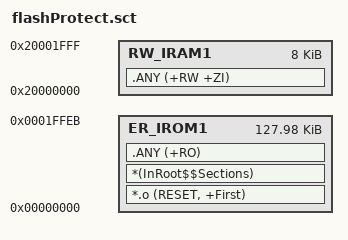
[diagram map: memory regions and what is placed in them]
; *************************************************************
; *** Scatter-Loading Description File modified so that     ***
; 0x0001ffec to 0x0001ffff aren't written by user code and  ***
; therefore can be used to store FAKEY and write protection ***
; key                                                       ***
; *************************************************************

LR_IROM1 0x00000000 0x0001ffec  {    ; load region size_region
  ER_IROM1 0x00000000 0x0001ffec  {  ; load address = execution address
   *.o (RESET, +First)
   *(InRoot$$Sections)
   .ANY (+RO)
  }
  RW_IRAM1 0x20000000 0x00002000  {  ; RW data
   .ANY (+RW +ZI)
  }
}

